# STM32F301x register map
File version: 1.0
Registers are 32-bit, read-write, reset 0x0 unless marked. A register's access mark holds for its fields unless they carry their own. Offsets are from the block's base; [hi:lo] are bit positions.

## PWR — Power control
Base 0x40007000
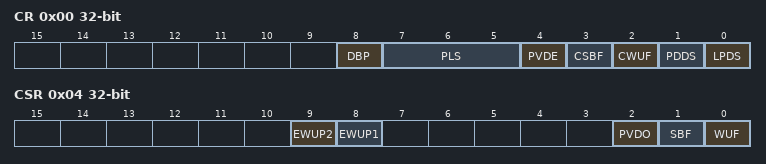
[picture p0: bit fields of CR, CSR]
0x00 CR — power control register
  [8] DBP — Disable backup domain write protection
  [7:5] PLS — PVD level selection
  [4] PVDE — Power voltage detector enable
  [3] CSBF — Clear standby flag
  [2] CWUF — Clear wakeup flag
  [1] PDDS — Power down deepsleep
  [0] LPDS — Low-power deep sleep
0x04 CSR access per field — power control/status register
  [9] EWUP2 rw — Enable WKUP2 pin
  [8] EWUP1 rw — Enable WKUP1 pin
  [2] PVDO ro — PVD output
  [1] SBF ro — Standby flag
  [0] WUF ro — Wakeup flag

## IWDG — Independent watchdog
Base 0x40003000
0x00 KR wo — Key register
  [15:0] KEY — Key value
0x04 PR — Prescaler register
  [2:0] PR — Prescaler divider
0x08 RLR reset 0xFFF — Reload register
  [11:0] RL — Watchdog counter reload value
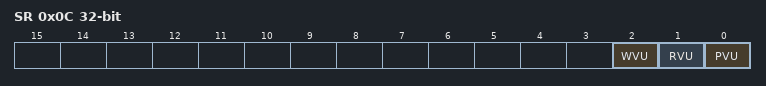
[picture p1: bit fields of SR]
0x0C SR ro — Status register
  [2] WVU — Watchdog counter window value update
  [1] RVU — Watchdog counter reload value update
  [0] PVU — Watchdog prescaler value update
0x10 WINR reset 0xFFF — Window register
  [11:0] WIN — Watchdog counter window value

## WWDG — Window watchdog
Base 0x40002C00
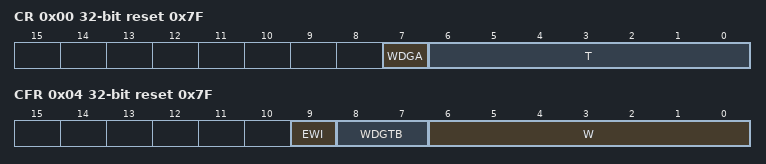
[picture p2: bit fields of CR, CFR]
0x00 CR reset 0x7F — Control register
  [7] WDGA — Activation bit
  [6:0] T — 7-bit counter
0x04 CFR reset 0x7F — Configuration register
  [9] EWI — Early wakeup interrupt
  [8:7] WDGTB — Timer base
  [6:0] W — 7-bit window value
0x08 SR — Status register
  [0] EWIF — Early wakeup interrupt flag

## TIM6 — Basic timers
Base 0x40001000
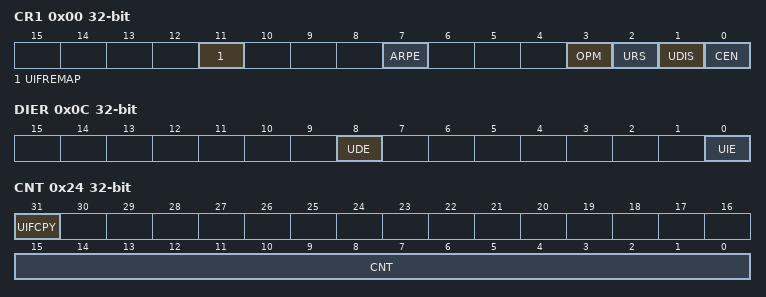
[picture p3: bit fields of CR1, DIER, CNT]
0x00 CR1 — control register 1
  [11] UIFREMAP — UIF status bit remapping
  [7] ARPE — Auto-reload preload enable
  [3] OPM — One-pulse mode
  [2] URS — Update request source
  [1] UDIS — Update disable
  [0] CEN — Counter enable
0x04 CR2 — control register 2
  [6:4] MMS — Master mode selection
0x0C DIER — DMA/Interrupt enable register
  [8] UDE — Update DMA request enable
  [0] UIE — Update interrupt enable
0x10 SR — status register
  [0] UIF — Update interrupt flag
0x14 EGR wo — event generation register
  [0] UG — Update generation
0x24 CNT access per field — counter
  [31] UIFCPY ro — UIF Copy
  [15:0] CNT rw — Low counter value
0x28 PSC — prescaler
  [15:0] PSC — Prescaler value
0x2C ARR — auto-reload register
  [15:0] ARR — Low Auto-reload value

## DAC — Digital-to-analog converter
Base 0x40007400
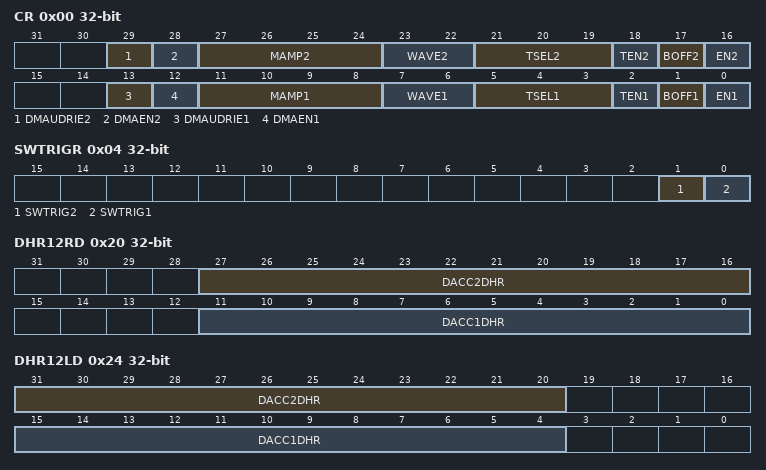
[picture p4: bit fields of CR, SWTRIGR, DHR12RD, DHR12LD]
0x00 CR — control register
  [29] DMAUDRIE2 — DAC channel2 DMA underrun interrupt enable
  [28] DMAEN2 — DAC channel2 DMA enable
  [27:24] MAMP2 — DAC channel2 mask/amplitude selector
  [23:22] WAVE2 — DAC channel2 noise/triangle wave generation enable
  [21:19] TSEL2 — DAC channel2 trigger selection
  [18] TEN2 — DAC channel2 trigger enable
  [17] BOFF2 — DAC channel2 output buffer disable
  [16] EN2 — DAC channel2 enable
  [13] DMAUDRIE1 — DAC channel1 DMA Underrun Interrupt enable
  [12] DMAEN1 — DAC channel1 DMA enable
  [11:8] MAMP1 — DAC channel1 mask/amplitude selector
  [7:6] WAVE1 — DAC channel1 noise/triangle wave generation enable
  [5:3] TSEL1 — DAC channel1 trigger selection
  [2] TEN1 — DAC channel1 trigger enable
  [1] BOFF1 — DAC channel1 output buffer disable
  [0] EN1 — DAC channel1 enable
0x04 SWTRIGR wo — software trigger register
  [1] SWTRIG2 — DAC channel2 software trigger
  [0] SWTRIG1 — DAC channel1 software trigger
0x08 DHR12R1 — channel1 12-bit right-aligned data holding register
  [11:0] DACC1DHR — DAC channel1 12-bit right-aligned data
0x0C DHR12L1 — channel1 12-bit left aligned data holding register
  [15:4] DACC1DHR — DAC channel1 12-bit left-aligned data
0x10 DHR8R1 — channel1 8-bit right aligned data holding register
  [7:0] DACC1DHR — DAC channel1 8-bit right-aligned data
0x14 DHR12R2 — channel2 12-bit right aligned data holding register
  [11:0] DACC2DHR — DAC channel2 12-bit right-aligned data
0x18 DHR12L2 — channel2 12-bit left aligned data holding register
  [15:4] DACC2DHR — DAC channel2 12-bit left-aligned data
0x1C DHR8R2 — channel2 8-bit right-aligned data holding register
  [7:0] DACC2DHR — DAC channel2 8-bit right-aligned data
0x20 DHR12RD — Dual DAC 12-bit right-aligned data holding register
  [27:16] DACC2DHR — DAC channel2 12-bit right-aligned data
  [11:0] DACC1DHR — DAC channel1 12-bit right-aligned data
0x24 DHR12LD — DUAL DAC 12-bit left aligned data holding register
  [31:20] DACC2DHR — DAC channel2 12-bit left-aligned data
  [15:4] DACC1DHR — DAC channel1 12-bit left-aligned data
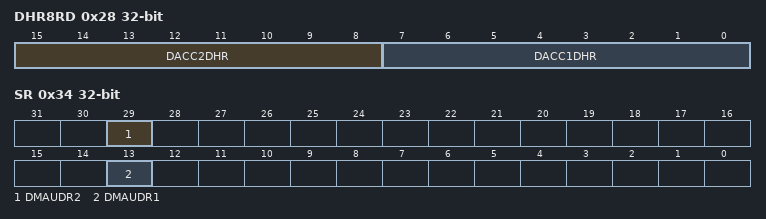
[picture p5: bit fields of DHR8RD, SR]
0x28 DHR8RD — DUAL DAC 8-bit right aligned data holding register
  [15:8] DACC2DHR — DAC channel2 8-bit right-aligned data
  [7:0] DACC1DHR — DAC channel1 8-bit right-aligned data
0x2C DOR1 ro — channel1 data output register
  [11:0] DACC1DOR — DAC channel1 data output
0x30 DOR2 ro — channel2 data output register
  [11:0] DACC2DOR — DAC channel2 data output
0x34 SR — status register
  [29] DMAUDR2 — DAC channel2 DMA underrun flag
  [13] DMAUDR1 — DAC channel1 DMA underrun flag
